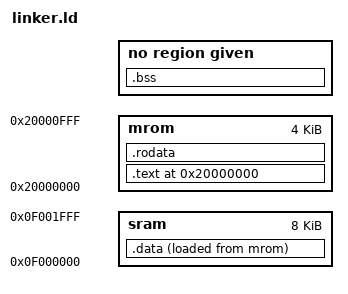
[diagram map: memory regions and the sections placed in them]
ENTRY(_start)
PHDRS { text PT_LOAD; data PT_LOAD; }

MEMORY {
  mrom : ORIGIN = 0x20000000, LENGTH = 4K
  sram : ORIGIN = 0x0f000000, LENGTH = 8K
}

SECTIONS {
  /* _pmem_start and _entry_offset are defined in LDFLAGS */
  /* Change to VMA & LMA version */
  . = ORIGIN(mrom);
  .text : {
    *(entry)
    *(.text*)
  } > mrom AT> mrom : text
  etext = .;
  _etext = .;
  .rodata : {
    *(.rodata*)
  } > mrom AT> mrom
  .data : ALIGN(4) {
    vma_data_start = .;
    *(.data*)
    *(.sdata*)
    vma_data_end = .;
  } > sram AT> mrom : data
  lma_data_start = LOADADDR(.data); 
  edata = .;
  _data = .;
  .bss : {
	_bss_start = .;
    *(.bss*)
    *(.sbss*)
    *(.scommon)
  }
  _stack_top = ORIGIN(sram) + 0x100; 
  . = _stack_top + 0x100;
  _stack_pointer = .;
  end = .;
  _end = .;
  _heap_start = ALIGN(0x1000);
}
